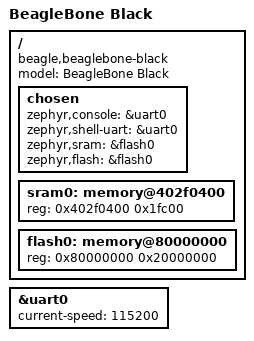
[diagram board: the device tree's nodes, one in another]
/*
 * Copyright (c) 2026 Manikanda Bharathi
 *
 * SPDX-License-Identifier: Apache-2.0
 */

/dts-v1/;
#include <arm/ti/am335x/am335x.dtsi>

/ {
	model = "BeagleBone Black";
	compatible = "beagle,beaglebone-black", "ti,am335x";

	chosen {
		zephyr,console = &uart0;
		zephyr,shell-uart = &uart0;
		zephyr,sram = &flash0;
		zephyr,flash = &flash0;
	};

	sram0: memory@402f0400 {
		device_type = "memory";
		reg = <0x402f0400 0x1fc00>;
	};

	flash0: memory@80000000 {
		device_type = "memory";
		reg = <0x80000000 0x20000000>;
	};
};

&uart0 {
	status = "okay";
	current-speed = <115200>;
};
